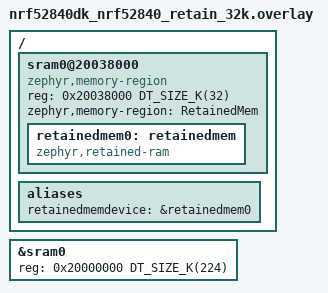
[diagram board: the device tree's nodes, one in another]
/ {
	sram0@20038000 {
		compatible = "zephyr,memory-region", "mmio-sram";
		reg = <0x20038000 DT_SIZE_K(32)>;
		zephyr,memory-region = "RetainedMem";
		status = "okay";

		retainedmem0: retainedmem {
			compatible = "zephyr,retained-ram";
			status = "okay";
		};
	};

	aliases {
		retainedmemdevice = &retainedmem0;
	};
};

&sram0 {
	/* Shrink SRAM size to avoid overlap with retained memory region */
	reg = <0x20000000 DT_SIZE_K(224)>;
};
